# SWM241 register map
File version: 1.0
SWM241 Microcontroller registers
CPU: CM0 r1p0, little endian, 2 interrupt priority bits
Registers are 32-bit, read-write, no defined reset value unless marked. A register's access mark holds for its fields unless they carry their own. Offsets are from the block's base; lines under a group give offsets from that group; [hi:lo] are bit positions; {n}, {i} and the like mark numbered series; 'fields as' and 'values as' point back to an identical list; <NAME> marks a mode.

## Memory map
0x40000000 SYS size 0xAA054 — Registers group
0x40000800 DMA size 0xC0 — Registers group
0x40002800 CRC size 0x10 — Registers group
0x40003800 DIV size 0x28 — Registers group
0x40040000 GPIOA size 0x80 — Registers group
0x40040800 GPIOB size 0x80
0x40041000 GPIOC size 0x80
0x40041800 GPIOD size 0x80
0x40042000 UART0 size 0x20 — Registers group
0x40042800 UART1 size 0x20
0x40043000 UART2 size 0x20
0x40043800 UART3 size 0x20
0x40044000 SPI0 size 0x14 — Registers group
0x40044800 SPI1 size 0x14
0x40046000 PWM0 size 0x40 — Registers group
0x40046040 PWM1 size 0x40
0x40046080 PWM2 size 0x40
0x400460C0 PWM3 size 0x40
0x40046200 PWMG size 0x4C — Registers group
0x40046800 TIMR0 size 0x34 — Registers group
0x40046840 TIMR1 size 0x34
0x40046880 TIMR2 size 0x34
0x400468C0 TIMR3 size 0x34
0x40046900 TIMR4 size 0x34
0x40046940 TIMR5 size 0x34
0x40046980 TIMR6 size 0x34
0x400469C0 TIMR7 size 0x34
0x40046C00 TIMRG size 0x44 — Registers group
0x40049000 ADC size 0x1FC — Registers group
0x4004A000 FMC size 0x2C — Registers group
0x4004B800 RTC size 0x6C — Registers group
0x400A0000 PORTA size 0x404 — Registers group
0x400A0010 PORTB size 0x404
0x400A0020 PORTC size 0x404
0x400A0030 PORTD size 0x404
0x400A0800 WDT size 0x14 — Registers group
0x400A6000 I2C0 size 0x38 — Registers group
0x400A6800 I2C1 size 0x38
0x400A8000 CAN size 0x3C0 — Registers group
0x400A9800 SLCD size 0x20 — Registers group
0x400AA800 SLED size 0x30 — Registers group
0x400AB000 SAFETY size 0x40 — Registers group

## SYS — Registers group
Base 0x40000000
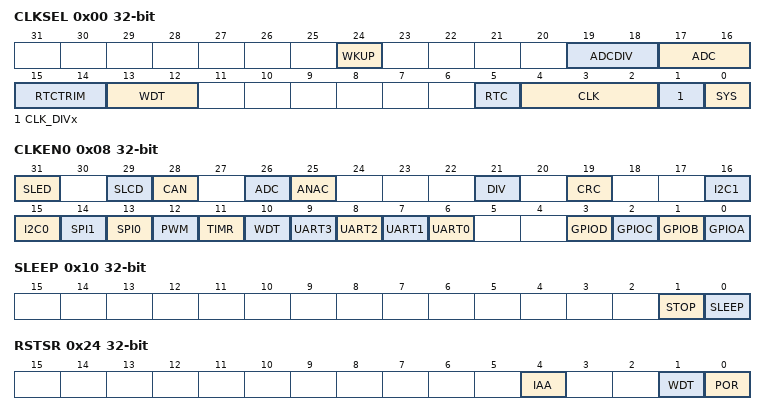
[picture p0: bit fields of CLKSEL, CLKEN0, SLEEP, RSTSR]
0x00 CLKSEL
  [24] WKUP, [19:18] ADCDIV, [17:16] ADC, [15:14] RTCTRIM, [13:12] WDT, [5] RTC, [4:2] CLK, [1] CLK_DIVx, [0] SYS
0x04 CLKDIVx_ON
0x08 CLKEN0
  [31] SLED, [29] SLCD, [28] CAN, [26] ADC, [25] ANAC, [21] DIV, [19] CRC, [16] I2C1, [15] I2C0, [14] SPI1, [13] SPI0, [12] PWM, [11] TIMR, [10] WDT, [n+6] UART{n} (n=0..3), [3] GPIOD, [2] GPIOC, [1] GPIOB, [0] GPIOA
0x0C CLKEN1
  [19] RTC
0x10 SLEEP
  [1] STOP, [0] SLEEP
0x24 RSTSR
  [4] IAA, [1] WDT, [0] POR
0x30 RTCWKCR
  [0] EN
0x34 RTCWKSR
  [0] FLAG
0x40 SYSIE
0x44 SYSIF
0x48 RAMERR
{0x80+4i} CHIPID[{i}] (i=0..3) ro
0xD0 PRNGCR
0xD4 PRNGDL
0xD8 PRNGDH
0x100 PAWKEN
0x104 PBWKEN
0x108 PCWKEN
0x10C PDWKEN
0x130 PAWKSR
0x134 PBWKSR
0x138 PCWKSR
0x13C PDWKSR
0x720 PRSTEN
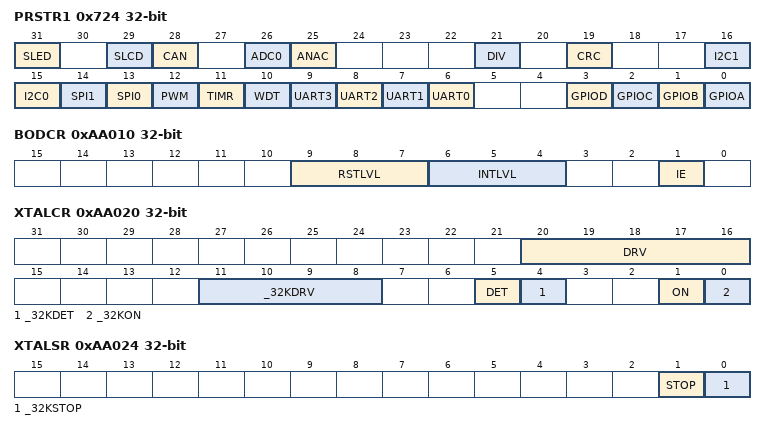
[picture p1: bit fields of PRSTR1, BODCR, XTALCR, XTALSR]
0x724 PRSTR1
  [31] SLED, [29] SLCD, [28] CAN, [26] ADC0, [25] ANAC, [21] DIV, [19] CRC, [16] I2C1, [15] I2C0, [14] SPI1, [13] SPI0, [12] PWM, [11] TIMR, [10] WDT, [n+6] UART{n} (n=0..3), [3] GPIOD, [2] GPIOC, [1] GPIOB, [0] GPIOA
0x728 PRSTR2
  [19] RTC
0xAA000 HRCCR
  [0] ON
0xAA010 BODCR
  [9:7] RSTLVL, [6:4] INTLVL, [1] IE
0xAA014 BODSR
  [0] IF
0xAA020 XTALCR
  [20:16] DRV, [11:8] _32KDRV, [5] DET, [4] _32KDET, [1] ON, [0] _32KON
0xAA024 XTALSR
  [1] STOP, [0] _32KSTOP
0xAA050 LRCCR
  [0] ON

## PORTA — Registers group
Base 0x400A0000
Same registers: PORTB 0x400A0010, PORTC 0x400A0020, PORTD 0x400A0030
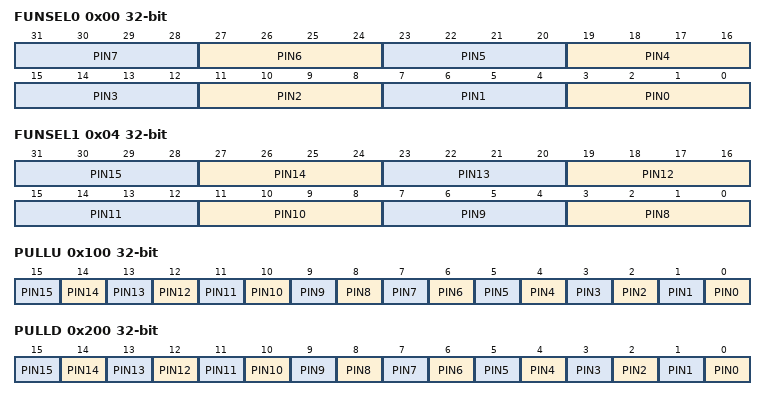
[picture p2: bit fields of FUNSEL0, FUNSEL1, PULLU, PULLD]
0x00 FUNSEL0
  [4n+3:4n] PIN{n} (n=0..7)
0x04 FUNSEL1
  [4n-29:4n-32] PIN{n} (n=8..15)
0x100 PULLU
  [n] PIN{n} (n=0..15)
0x200 PULLD
  [n] PIN{n} (n=0..15)
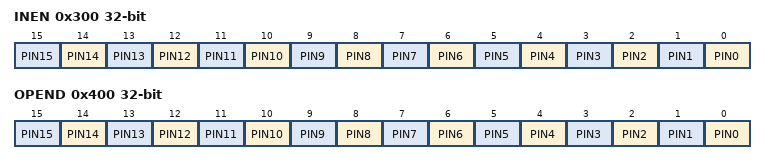
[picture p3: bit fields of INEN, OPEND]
0x300 INEN
  [n] PIN{n} (n=0..15)
0x400 OPEND
  [n] PIN{n} (n=0..15)

## GPIOA — Registers group
Base 0x40040000
Same registers: GPIOB 0x40040800, GPIOC 0x40041000, GPIOD 0x40041800
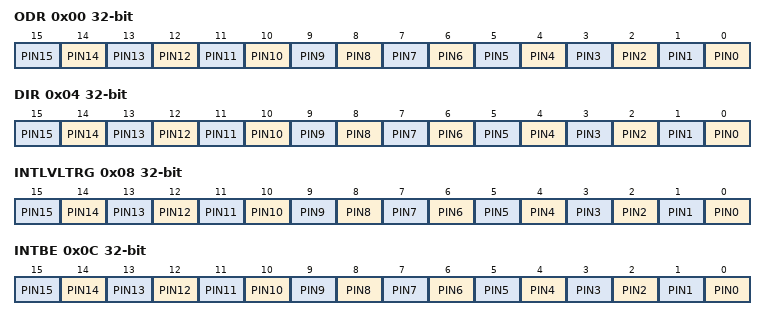
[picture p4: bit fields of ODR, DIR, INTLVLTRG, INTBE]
0x00 ODR
  [n] PIN{n} (n=0..15)
0x04 DIR
  [n] PIN{n} (n=0..15)
0x08 INTLVLTRG
  [n] PIN{n} (n=0..15)
0x0C INTBE
  [n] PIN{n} (n=0..15)
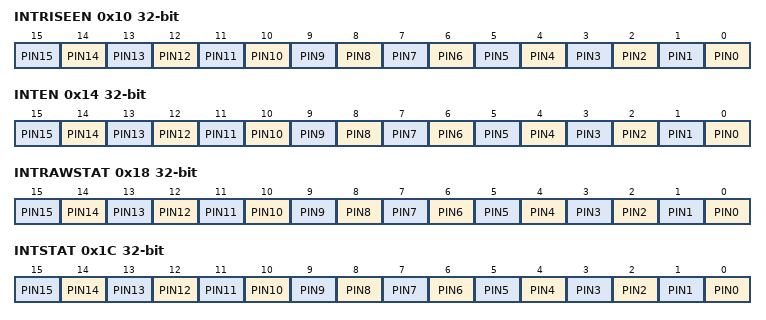
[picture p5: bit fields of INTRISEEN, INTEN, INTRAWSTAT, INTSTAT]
0x10 INTRISEEN
  [n] PIN{n} (n=0..15)
0x14 INTEN
  [n] PIN{n} (n=0..15)
0x18 INTRAWSTAT
  [n] PIN{n} (n=0..15)
0x1C INTSTAT
  [n] PIN{n} (n=0..15)
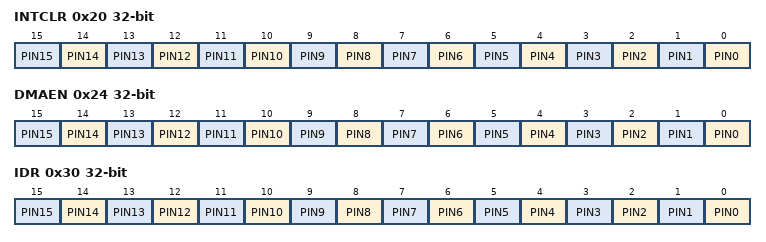
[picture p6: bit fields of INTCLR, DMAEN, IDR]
0x20 INTCLR
  [n] PIN{n} (n=0..15)
0x24 DMAEN
  [n] PIN{n} (n=0..15)
0x30 IDR
  [n] PIN{n} (n=0..15)
{0x40+4i} DATAPIN{i} (i=0..15)
